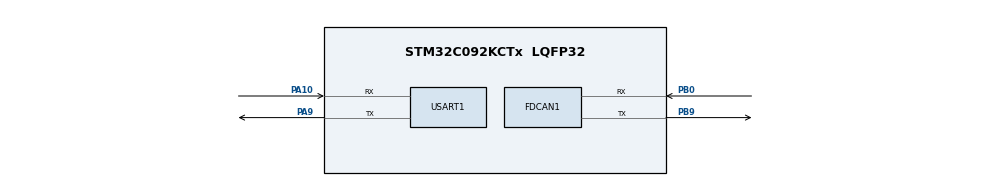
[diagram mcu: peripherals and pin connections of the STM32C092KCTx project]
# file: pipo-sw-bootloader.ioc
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FDCAN1.CalculateBaudRateNominal=250000
FDCAN1.CalculateTimeBitNominal=4000
FDCAN1.CalculateTimeQuantumNominal=1333.3333333333333
Mcu.Family=STM32C0
Mcu.Name=STM32C092KCTx
Mcu.Package=LQFP32
PA10.Mode=Asynchronous
PA10.Signal=USART1_RX
PA13.Mode=Serial_Wire
PA13.Signal=DEBUG_SWDIO
PA14-BOOT0.Mode=Serial_Wire
PA14-BOOT0.Signal=DEBUG_SWCLK
PA9.Mode=Asynchronous
PA9.Signal=USART1_TX
PB0.Mode=FDCAN_Activate
PB0.Signal=FDCAN1_RX
PB9.Mode=FDCAN_Activate
PB9.Signal=FDCAN1_TX
PC14-OSCX_IN(PC14).Mode=HSE-External-Oscillator
PC14-OSCX_IN(PC14).Signal=RCC_OSCX_IN
PC15-OSCX_OUT(PC15).Mode=HSE-External-Oscillator
PC15-OSCX_OUT(PC15).Signal=RCC_OSCX_OUT
ProjectManager.HeapSize=0x200
ProjectManager.StackSize=0x400
ProjectManager.TargetToolchain=Makefile
RCC.ADCFreq_Value=12000000
RCC.AHBFreq_Value=12000000
RCC.CortexFreq_Value=12000000
RCC.EXTERNAL_CLOCK_VALUE=12288000
RCC.HCLKFreq_Value=12000000
RCC.HSE_VALUE=8000000
RCC.HSI_VALUE=48000000
RCC.LSE_VALUE=32768
RCC.SYSCLKFreq_VALUE=12000000
USART1.VirtualMode-Asynchronous=VM_ASYNC
board=custom

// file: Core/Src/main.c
/* USER CODE BEGIN Header */
/**
  ******************************************************************************
  * @file           : main.c
  * @brief          : Main program body
  ******************************************************************************
  * @attention
  *
  * Copyright (c) 2026 STMicroelectronics.
  * All rights reserved.
  *
  * This software is licensed under terms that can be found in the LICENSE file
  * in the root directory of this software component.
  * If no LICENSE file comes with this software, it is provided AS-IS.
  *
  ******************************************************************************
  */
/* USER CODE END Header */
#include "main.h"
#include "fdcan.h"
#include "usart.h"
#include "gpio.h"

/* USER CODE BEGIN Includes */
#include "boot.h"
/* USER CODE END Includes */

void SystemClock_Config(void);

int main(void)
{

  /* MCU Configuration--------------------------------------------------------*/

  /* Reset of all peripherals, Initializes the Flash interface and the Systick. */
  HAL_Init();

  /* Configure the system clock */
  SystemClock_Config();

  /* Initialize all configured peripherals */
  MX_GPIO_Init();
  MX_FDCAN1_Init();
  MX_USART1_UART_Init();

  /* Infinite loop */
  /* USER CODE BEGIN WHILE */
  BootInit();
  HAL_UART_Transmit(&huart1, (uint8_t *)"Init Done", 10, 20);
  while (1)
  {
    BootTask();
    /* USER CODE END WHILE */

  }
}

void SystemClock_Config(void)
{
  RCC_OscInitTypeDef RCC_OscInitStruct = {0};
  RCC_ClkInitTypeDef RCC_ClkInitStruct = {0};

  __HAL_FLASH_SET_LATENCY(FLASH_LATENCY_0);

  /** Initializes the RCC Oscillators according to the specified parameters
  * in the RCC_OscInitTypeDef structure.
  */
  RCC_OscInitStruct.OscillatorType = RCC_OSCILLATORTYPE_HSI;
  RCC_OscInitStruct.HSIState = RCC_HSI_ON;
  RCC_OscInitStruct.HSIDiv = RCC_HSI_DIV4;
  RCC_OscInitStruct.HSICalibrationValue = RCC_HSICALIBRATION_DEFAULT;
  if (HAL_RCC_OscConfig(&RCC_OscInitStruct) != HAL_OK)
  {
    Error_Handler();
  }

  /** Initializes the CPU, AHB and APB buses clocks
  */
  RCC_ClkInitStruct.ClockType = RCC_CLOCKTYPE_HCLK|RCC_CLOCKTYPE_SYSCLK
                              |RCC_CLOCKTYPE_PCLK1;
  RCC_ClkInitStruct.SYSCLKSource = RCC_SYSCLKSOURCE_HSI;
  RCC_ClkInitStruct.SYSCLKDivider = RCC_SYSCLK_DIV1;
  RCC_ClkInitStruct.AHBCLKDivider = RCC_HCLK_DIV1;
  RCC_ClkInitStruct.APB1CLKDivider = RCC_APB1_DIV1;

  if (HAL_RCC_ClockConfig(&RCC_ClkInitStruct, FLASH_LATENCY_0) != HAL_OK)
  {
    Error_Handler();
  }
}

void Error_Handler(void)
{
  __disable_irq();
  while (1)
  {
  }
}
